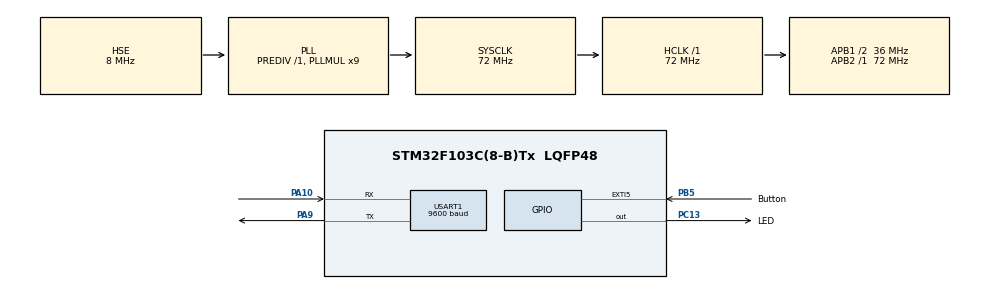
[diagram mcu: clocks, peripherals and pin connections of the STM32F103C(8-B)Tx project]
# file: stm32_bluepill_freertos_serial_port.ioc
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FREERTOS.Tasks01=LT,8,128,StartLT,Default,NULL,Dynamic,NULL,NULL;HT,40,128,StartHT,Default,NULL,Dynamic,NULL,NULL
Mcu.Family=STM32F1
Mcu.Name=STM32F103C(8-B)Tx
Mcu.Package=LQFP48
NVIC.EXTI9_5_IRQn=true\:2\:0\:true\:false\:true\:false\:true\:true
NVIC.PriorityGroup=NVIC_PRIORITYGROUP_4
NVIC.TIM4_IRQn=true\:0\:0\:false\:false\:true\:false\:false\:true
NVIC.TimeBase=TIM4_IRQn
NVIC.TimeBaseIP=TIM4
PA10.Mode=Asynchronous
PA10.Signal=USART1_RX
PA13.Mode=Serial_Wire
PA13.Signal=SYS_JTMS-SWDIO
PA14.Mode=Serial_Wire
PA14.Signal=SYS_JTCK-SWCLK
PA9.Mode=Asynchronous
PA9.Signal=USART1_TX
PB5.GPIO_Label=Button
PB5.GPIO_ModeDefaultEXTI=GPIO_MODE_IT_FALLING
PB5.GPIO_PuPd=GPIO_PULLUP
PB5.Signal=GPXTI5
PC13-TAMPER-RTC.GPIO_Label=LED
PC13-TAMPER-RTC.GPIO_Speed=GPIO_SPEED_FREQ_HIGH
PC13-TAMPER-RTC.Signal=GPIO_Output
PD0-OSC_IN.Mode=HSE-External-Oscillator
PD0-OSC_IN.Signal=RCC_OSC_IN
PD1-OSC_OUT.Mode=HSE-External-Oscillator
PD1-OSC_OUT.Signal=RCC_OSC_OUT
ProjectManager.HeapSize=0x200
ProjectManager.StackSize=0x400
ProjectManager.TargetToolchain=STM32CubeIDE
RCC.AHBFreq_Value=72000000
RCC.APB1CLKDivider=RCC_HCLK_DIV2
RCC.APB1Freq_Value=36000000
RCC.APB1TimFreq_Value=72000000
RCC.APB2Freq_Value=72000000
RCC.APB2TimFreq_Value=72000000
RCC.HCLKFreq_Value=72000000
RCC.PLLMUL=RCC_PLL_MUL9
RCC.PLLSourceVirtual=RCC_PLLSOURCE_HSE
RCC.SYSCLKFreq_VALUE=72000000
RCC.SYSCLKSource=RCC_SYSCLKSOURCE_PLLCLK
RCC.USBFreq_Value=72000000
USART1.BaudRate=9600
USART1.VirtualMode=VM_ASYNC
VP_FREERTOS_VS_CMSIS_V2.Mode=CMSIS_V2
VP_SYS_VS_tim4.Mode=TIM4
board=custom

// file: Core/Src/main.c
/* USER CODE BEGIN Header */
/**
  ******************************************************************************
  * @file           : main.c
  * @brief          : Main program body
  ******************************************************************************
  * @attention
  *
  * <h2><center>&copy; Copyright (c) 2020 STMicroelectronics.
  * All rights reserved.</center></h2>
  *
  * This software component is licensed by ST under BSD 3-Clause license,
  * the "License"; You may not use this file except in compliance with the
  * License. You may obtain a copy of the License at:
  *                        opensource.org/licenses/BSD-3-Clause
  *
  ******************************************************************************
  */
/* USER CODE END Header */
#include "main.h"
#include "cmsis_os.h"

UART_HandleTypeDef huart1;

/* Definitions for LT */
osThreadId_t LTHandle;
const osThreadAttr_t LT_attributes = {
  .name = "LT",
  .priority = (osPriority_t) osPriorityLow,
  .stack_size = 128 * 4
};
/* Definitions for HT */
osThreadId_t HTHandle;
const osThreadAttr_t HT_attributes = {
  .name = "HT",
  .priority = (osPriority_t) osPriorityHigh,
  .stack_size = 128 * 4
};

void SystemClock_Config(void);
static void MX_GPIO_Init(void);
static void MX_USART1_UART_Init(void);
void StartLT(void *argument);
void StartHT(void *argument);

/* USER CODE BEGIN 0 */
void send_string(char* s)
{
	HAL_UART_Transmit(&huart1, (uint8_t*)s, strlen(s), 1000);
}

void send_char(char c)
{
	HAL_UART_Transmit(&huart1, (uint8_t*)&c, 1, 1000);
}

int __io_putchar(int ch)
{
	send_char(ch);
	return ch;
}
/* USER CODE END 0 */

int main(void)
{

  /* MCU Configuration--------------------------------------------------------*/

  /* Reset of all peripherals, Initializes the Flash interface and the Systick. */
  HAL_Init();

  /* Configure the system clock */
  SystemClock_Config();

  /* Initialize all configured peripherals */
  MX_GPIO_Init();
  MX_USART1_UART_Init();

  /* Init scheduler */
  osKernelInitialize();

  /* Create the thread(s) */
  /* creation of LT */
  LTHandle = osThreadNew(StartLT, NULL, &LT_attributes);

  /* creation of HT */
  HTHandle = osThreadNew(StartHT, NULL, &HT_attributes);

  /* Start scheduler */
  osKernelStart();

  /* We should never get here as control is now taken by the scheduler */
  /* Infinite loop */
  while (1)
  {

  }
}

void SystemClock_Config(void)
{
  RCC_OscInitTypeDef RCC_OscInitStruct = {0};
  RCC_ClkInitTypeDef RCC_ClkInitStruct = {0};

  /** Initializes the RCC Oscillators according to the specified parameters
  * in the RCC_OscInitTypeDef structure.
  */
  RCC_OscInitStruct.OscillatorType = RCC_OSCILLATORTYPE_HSE;
  RCC_OscInitStruct.HSEState = RCC_HSE_ON;
  RCC_OscInitStruct.HSEPredivValue = RCC_HSE_PREDIV_DIV1;
  RCC_OscInitStruct.HSIState = RCC_HSI_ON;
  RCC_OscInitStruct.PLL.PLLState = RCC_PLL_ON;
  RCC_OscInitStruct.PLL.PLLSource = RCC_PLLSOURCE_HSE;
  RCC_OscInitStruct.PLL.PLLMUL = RCC_PLL_MUL9;
  if (HAL_RCC_OscConfig(&RCC_OscInitStruct) != HAL_OK)
  {
    Error_Handler();
  }
  /** Initializes the CPU, AHB and APB buses clocks
  */
  RCC_ClkInitStruct.ClockType = RCC_CLOCKTYPE_HCLK|RCC_CLOCKTYPE_SYSCLK
                              |RCC_CLOCKTYPE_PCLK1|RCC_CLOCKTYPE_PCLK2;
  RCC_ClkInitStruct.SYSCLKSource = RCC_SYSCLKSOURCE_PLLCLK;
  RCC_ClkInitStruct.AHBCLKDivider = RCC_SYSCLK_DIV1;
  RCC_ClkInitStruct.APB1CLKDivider = RCC_HCLK_DIV2;
  RCC_ClkInitStruct.APB2CLKDivider = RCC_HCLK_DIV1;

  if (HAL_RCC_ClockConfig(&RCC_ClkInitStruct, FLASH_LATENCY_2) != HAL_OK)
  {
    Error_Handler();
  }
}

static void MX_USART1_UART_Init(void)
{

  huart1.Instance = USART1;
  huart1.Init.BaudRate = 9600;
  huart1.Init.WordLength = UART_WORDLENGTH_8B;
  huart1.Init.StopBits = UART_STOPBITS_1;
  huart1.Init.Parity = UART_PARITY_NONE;
  huart1.Init.Mode = UART_MODE_TX_RX;
  huart1.Init.HwFlowCtl = UART_HWCONTROL_NONE;
  huart1.Init.OverSampling = UART_OVERSAMPLING_16;
  if (HAL_UART_Init(&huart1) != HAL_OK)
  {
    Error_Handler();
  }

}

static void MX_GPIO_Init(void)
{
  GPIO_InitTypeDef GPIO_InitStruct = {0};

  /* GPIO Ports Clock Enable */
  __HAL_RCC_GPIOC_CLK_ENABLE();
  __HAL_RCC_GPIOD_CLK_ENABLE();
  __HAL_RCC_GPIOA_CLK_ENABLE();
  __HAL_RCC_GPIOB_CLK_ENABLE();

  /*Configure GPIO pin Output Level */
  HAL_GPIO_WritePin(LED_GPIO_Port, LED_Pin, GPIO_PIN_RESET);

  /*Configure GPIO pin : LED_Pin */
  GPIO_InitStruct.Pin = LED_Pin;
  GPIO_InitStruct.Mode = GPIO_MODE_OUTPUT_PP;
  GPIO_InitStruct.Pull = GPIO_NOPULL;
  GPIO_InitStruct.Speed = GPIO_SPEED_FREQ_HIGH;
  HAL_GPIO_Init(LED_GPIO_Port, &GPIO_InitStruct);

  /*Configure GPIO pin : Button_Pin */
  GPIO_InitStruct.Pin = Button_Pin;
  GPIO_InitStruct.Mode = GPIO_MODE_IT_FALLING;
  GPIO_InitStruct.Pull = GPIO_PULLUP;
  HAL_GPIO_Init(Button_GPIO_Port, &GPIO_InitStruct);

  /* EXTI interrupt init*/
  HAL_NVIC_SetPriority(EXTI9_5_IRQn, 2, 0);
  HAL_NVIC_EnableIRQ(EXTI9_5_IRQn);

}

void StartLT(void *argument)
{
  /* USER CODE BEGIN 5 */
  /* Infinite loop */
  for(;;)
  {
	  printf("LT transmiting\n");
	  osDelay(1000);
  }
  /* USER CODE END 5 */
}

void StartHT(void *argument)
{
  /* USER CODE BEGIN StartHT */
  /* Infinite loop */
  for(;;)
  {
	  printf("HT transmiting\n");
	  osDelay(2000);
  }
  /* USER CODE END StartHT */
}

void HAL_TIM_PeriodElapsedCallback(TIM_HandleTypeDef *htim)
{
  if (htim->Instance == TIM4) {
    HAL_IncTick();
  }
}

void Error_Handler(void)
{
}

/************************ (C) COPYRIGHT STMicroelectronics *****END OF FILE****/
